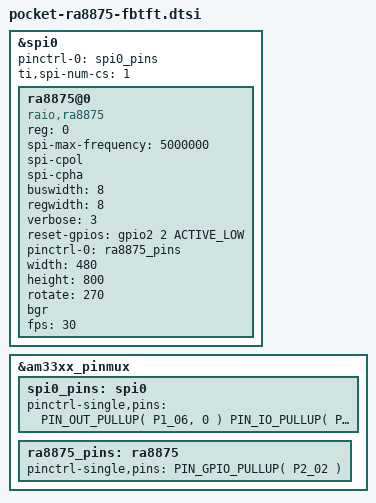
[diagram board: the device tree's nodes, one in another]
#include "subarctic/pinctrl.h"
#include "gpio.h"
#include "bone/pocket.h"

// RA8875 display driver connected via spi to PocketBeagle
//
// fb-tft kernel driver version -- XXX DRAFT OUTLINE XXX
//
// Based on the confusing discussion at:
//	https://github.com/notro/fbtft/issues/96

USES_PIN(P1_06);  // -> spi cs
USES_PIN(P1_08);  // -> spi clk
USES_PIN(P1_10);  // <- spi miso
USES_PIN(P1_12);  // -> spi mosi
USES_PIN(P2_02);  // -> reset
//USES_PIN(P2_04);  // <- wait
//USES_PIN(P2_06);  // <- irq

&spi0 {
	status = "okay";

	pinctrl-names = "default";
	pinctrl-0 = <&spi0_pins>;

	ti,spi-num-cs = <1>;

	ra8875@0 {
		reg = <0>;

		// max spi frequency is:
		//	sys_clk/3 for write
		//	sys_clk/6 for read (not used by kernel driver)
		// sys_clk is min 1 MHz, typ 20-30 MHz, max 60 MHz
		// sys_clk defaults to Fosc (crystal osc)
		// Fosc is min 15 MHz, typ 20 MHz, max 30 MHz
		//
		// XXX kernel driver hardcodes 1 MHz
		//
		spi-max-frequency = <5000000>;

		// SPI mode 3
		spi-cpol;
		spi-cpha;

		// fb-tft ra8875 kernel driver
		compatible = "raio,ra8875";
		buswidth = <8>;
		regwidth = <8>;
		verbose = <3>;
		//debug = <7>;

		reset-gpios = <&gpio2 2 ACTIVE_LOW>;
		//dc-gpios = ...;   // XXX makes no sense

		pinctrl-names = "default";
		pinctrl-0 = <&ra8875_pins>;

		// display parameters
		width= <480>;
		height= <800>;
		rotate = <270>;
		bgr;
		fps = <30>;
	};
};

&am33xx_pinmux {
	spi0_pins: spi0 {
		pinctrl-single,pins = <
			PIN_OUT_PULLUP( P1_06, 0 )  // cs 0
			PIN_IO_PULLUP(  P1_08, 0 )  // clk
			PIN_IN_PULLUP(  P1_10, 0 )  // d0 miso
			PIN_OUT_PULLUP( P1_12, 0 )  // d1 mosi
		>;
	};

	ra8875_pins: ra8875 {
		pinctrl-single,pins = <
			PIN_GPIO_PULLUP( P2_02 )  // io 1.27 reset
		//	PIN_GPIN_PULLUP( P2_04 )  // io 1.26 wait
		//	PIN_GPIN_PULLUP( P2_06 )  // io 1.25 irq
		>;
	};
};
